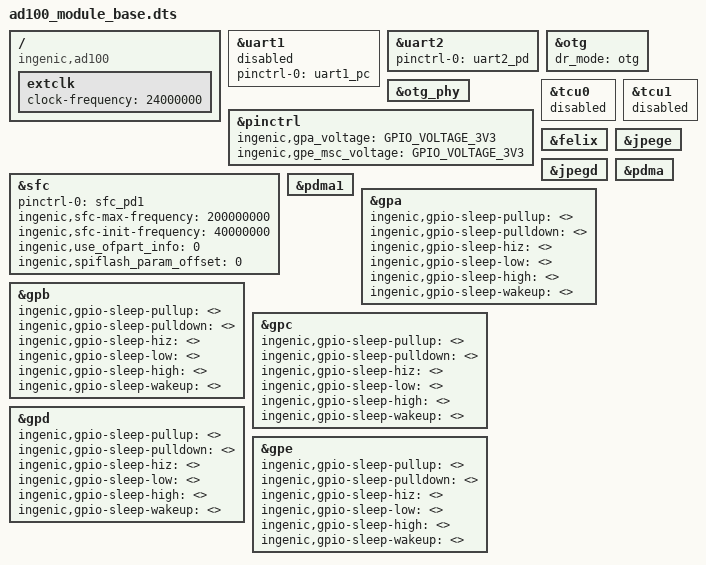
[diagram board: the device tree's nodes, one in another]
/dts-v1/;

#include <dt-bindings/input/input.h>
#include "ad100.dtsi"
#include <dt-bindings/interrupt-controller/irq.h>
#include <generated/autoconf.h>

/*
    reserved-memory 大小说明：（需要的最小值）
    解码使用的内存大小， 使用libhardware2的解码接口：(felix->max_frames_buffer + 1) * frame_size

	例如：1080p h264的解码不带B帧的情况下，需要预留的内存大小：
	dec_mem:
         frame_size = 1920 * 1080 * 3 / 2 = 3110400;
         felix->max_frames_buffer = 6（默认等于6，可以通过修改模块参数的值来修改,例如：
                                       echo 3 > /sys/module/ingenic_felix/parameters/max_frame_buffers)
         dec_mem = max_frames_buffer + 1 * frame_size
                     = (6 + 1) * 3110400
                     = 20.8M
		同理算出720p需要内存为 (6 + 1) * 1280 * 720 * 3 / 2 = 9.2M
        ps:
          1.计算出来的内存为极限值，需要多预留
          2.此为使用libhardware2 接口内存计算方式，若使用ffmpeg以ffmpeg实际使用为准
*/

/ {
	compatible = "ingenic,ad100";
	/*chosen {
		bootargs = "console=ttyS0,115200 mem=64M@0x0 ip=off init=/linuxrc ubi.mtd=2 root=ubi0:rootfs ubi.mtd=3 rootfstype=ubifs rw flashtype=nand";
	};*/

	/*
		reserved_mem@5000000: 对应预留内存地址起始位置为0x5000000
		reg = <0x05000000 0x2000000>: 分别对应起始位置为0x05000000, 大小为0x2000000
		配置的凭据以此芯片ad100为例, 内存总大小为64M, 即总大小为0x4000000
		ad100通用对应的uboot配置里设置了RMEM_MB=8, 因此总地址的后8M会被RMEM占用, 则剩余内存大小为0x3800000
		由此当我们分配10M预留内存给reserved_memory时, 起始地址则为0x3800000-0xA00000 = 0x2E00000, 大小为0xA00000
		如果需要改变此区域大小, 需要同时修改起始地址和大小(reserved_mem@2E00000 和 reg = <0x2E00000 0xA00000> 的地址需要一起修改)
		需要用到该地址申请内存的驱动, 需要加上 memory-region=<&reserved_memory>; 详细参考下面 felix 等的用法
	*/

	/*reserved-memory {
		#address-cells = <1>;
		#size-cells = <1>;
		ranges =<>;

		reserved_memory: reserved_mem@2E00000{
			compatible = "shared-dma-pool";
			reg = <0x2E00000 0xA00000>;
		};*/
};

&uart1 {
	status = "disable";
	pinctrl-names = "default";
	pinctrl-0 = <&uart1_pc>;
};

&uart2 {
	status = "okay";
	pinctrl-names = "default";
	pinctrl-0 = <&uart2_pd>;
};

&otg {
	dr_mode = "otg"; // host,peripheral,otg
	status = "okay";
};

&otg_phy {
	status = "okay";
};

&pinctrl {
	ingenic,gpa_voltage = <GPIO_VOLTAGE_3V3>;
	ingenic,gpe_msc_voltage = <GPIO_VOLTAGE_3V3>;
};

&sfc {
	status = "okay";
	pinctrl-names = "default";
	pinctrl-0 = <&sfc_pd1>;
	ingenic,sfc-max-frequency = <200000000>;
	ingenic,sfc-init-frequency= <40000000>;
	ingenic,use_ofpart_info  = /bits/ 8 <0>;
	ingenic,spiflash_param_offset = <0>;

};

&tcu0 {
	status = "disable";
};

&tcu1 {
	status = "disable";
};

/ {

	extclk: extclk {
		clock-frequency = <24000000>;
	};
};

/* 加上 memory-region=<&reserved_memory>; 表示会用上方设置的预留内存地址和大小作为内存申请 */
&felix {
	status = "okay";
	/* memory-region=<&reserved_memory>; */
};

&jpege {
	status = "okay";
};

&jpegd {
	status = "okay";
};

&pdma {
	status = "okay";
};

&pdma1 {
	status = "okay";
};

/* Board Sleep GPIO configuration. */
/* <0 1 2 3 .... 31>, set one of the pin to state.*/

&gpa {
	ingenic,gpio-sleep-pullup 	= <>;
	ingenic,gpio-sleep-pulldown 	= <>;
	ingenic,gpio-sleep-hiz		= <>;
	ingenic,gpio-sleep-low		= <>;
	ingenic,gpio-sleep-high		= <>;
	ingenic,gpio-sleep-wakeup	= <>;
};

&gpb {
	ingenic,gpio-sleep-pullup 	= <>;
	ingenic,gpio-sleep-pulldown 	= <>;
	ingenic,gpio-sleep-hiz		= <>;
	ingenic,gpio-sleep-low		= <>;
	ingenic,gpio-sleep-high		= <>;
	ingenic,gpio-sleep-wakeup	= <>;
};

&gpc {
	ingenic,gpio-sleep-pullup 	= <>;
	ingenic,gpio-sleep-pulldown 	= <>;
	ingenic,gpio-sleep-hiz		= <>;
	ingenic,gpio-sleep-low		= <>;
	ingenic,gpio-sleep-high		= <>;
	ingenic,gpio-sleep-wakeup	= <>;
};

&gpd {
	ingenic,gpio-sleep-pullup 	= <>;
	ingenic,gpio-sleep-pulldown 	= <>;
	ingenic,gpio-sleep-hiz		= <>;
	ingenic,gpio-sleep-low		= <>;
	ingenic,gpio-sleep-high		= <>;
	ingenic,gpio-sleep-wakeup	= <>;
};

&gpe {
	ingenic,gpio-sleep-pullup 	= <>;
	ingenic,gpio-sleep-pulldown 	= <>;
	ingenic,gpio-sleep-hiz		= <>;
	ingenic,gpio-sleep-low		= <>;
	ingenic,gpio-sleep-high		= <>;
	ingenic,gpio-sleep-wakeup	= <>;
};
